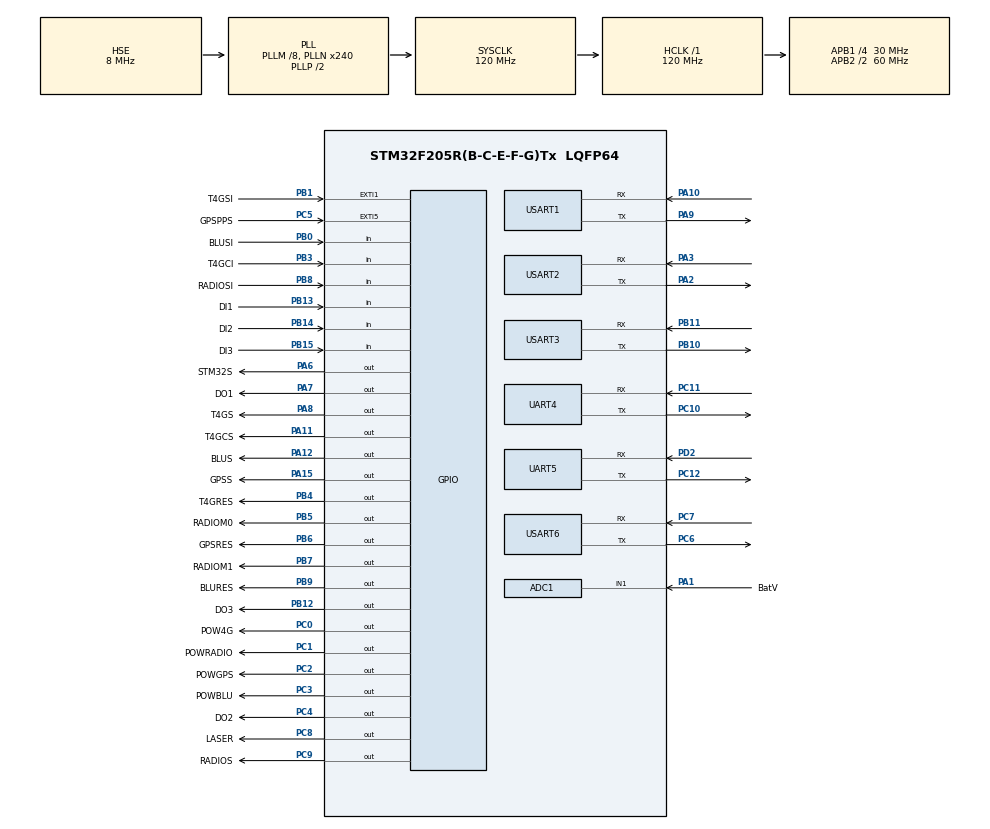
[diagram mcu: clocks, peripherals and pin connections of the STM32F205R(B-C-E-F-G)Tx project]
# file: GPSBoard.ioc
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ADC1.Channel-0\#ChannelRegularConversion=ADC_CHANNEL_1
ADC1.NbrOfConversionFlag=1
ADC1.Rank-0\#ChannelRegularConversion=1
ADC1.SamplingTime-0\#ChannelRegularConversion=ADC_SAMPLETIME_3CYCLES
ADC1.master=1
Dma.Request0=USART1_RX
Dma.Request1=USART1_TX
Dma.Request10=UART4_RX
Dma.Request11=UART4_TX
Dma.Request2=USART2_RX
Dma.Request3=USART2_TX
Dma.Request4=USART3_RX
Dma.Request5=USART3_TX
Dma.Request6=USART6_RX
Dma.Request7=USART6_TX
Dma.Request8=UART5_RX
Dma.Request9=UART5_TX
Dma.UART4_RX.10.Direction=DMA_PERIPH_TO_MEMORY
Dma.UART4_RX.10.FIFOMode=DMA_FIFOMODE_ENABLE
Dma.UART4_RX.10.FIFOThreshold=DMA_FIFO_THRESHOLD_FULL
Dma.UART4_RX.10.Instance=DMA1_Stream2
Dma.UART4_RX.10.MemBurst=DMA_MBURST_SINGLE
Dma.UART4_RX.10.MemDataAlignment=DMA_MDATAALIGN_BYTE
Dma.UART4_RX.10.MemInc=DMA_MINC_ENABLE
Dma.UART4_RX.10.Mode=DMA_NORMAL
Dma.UART4_RX.10.PeriphBurst=DMA_PBURST_SINGLE
Dma.UART4_RX.10.PeriphDataAlignment=DMA_PDATAALIGN_BYTE
Dma.UART4_RX.10.PeriphInc=DMA_PINC_DISABLE
Dma.UART4_RX.10.Priority=DMA_PRIORITY_LOW
Dma.UART4_TX.11.Direction=DMA_MEMORY_TO_PERIPH
Dma.UART4_TX.11.FIFOMode=DMA_FIFOMODE_ENABLE
Dma.UART4_TX.11.FIFOThreshold=DMA_FIFO_THRESHOLD_FULL
Dma.UART4_TX.11.Instance=DMA1_Stream4
Dma.UART4_TX.11.MemBurst=DMA_MBURST_SINGLE
Dma.UART4_TX.11.MemDataAlignment=DMA_MDATAALIGN_BYTE
Dma.UART4_TX.11.MemInc=DMA_MINC_ENABLE
Dma.UART4_TX.11.Mode=DMA_NORMAL
Dma.UART4_TX.11.PeriphBurst=DMA_PBURST_SINGLE
Dma.UART4_TX.11.PeriphDataAlignment=DMA_PDATAALIGN_BYTE
Dma.UART4_TX.11.PeriphInc=DMA_PINC_DISABLE
Dma.UART4_TX.11.Priority=DMA_PRIORITY_LOW
Dma.UART5_RX.8.Direction=DMA_PERIPH_TO_MEMORY
Dma.UART5_RX.8.FIFOMode=DMA_FIFOMODE_ENABLE
Dma.UART5_RX.8.FIFOThreshold=DMA_FIFO_THRESHOLD_FULL
Dma.UART5_RX.8.Instance=DMA1_Stream0
Dma.UART5_RX.8.MemBurst=DMA_MBURST_SINGLE
Dma.UART5_RX.8.MemDataAlignment=DMA_MDATAALIGN_BYTE
Dma.UART5_RX.8.MemInc=DMA_MINC_ENABLE
Dma.UART5_RX.8.Mode=DMA_NORMAL
Dma.UART5_RX.8.PeriphBurst=DMA_PBURST_SINGLE
Dma.UART5_RX.8.PeriphDataAlignment=DMA_PDATAALIGN_BYTE
Dma.UART5_RX.8.PeriphInc=DMA_PINC_DISABLE
Dma.UART5_RX.8.Priority=DMA_PRIORITY_LOW
Dma.UART5_TX.9.Direction=DMA_MEMORY_TO_PERIPH
Dma.UART5_TX.9.FIFOMode=DMA_FIFOMODE_ENABLE
Dma.UART5_TX.9.FIFOThreshold=DMA_FIFO_THRESHOLD_FULL
Dma.UART5_TX.9.Instance=DMA1_Stream7
Dma.UART5_TX.9.MemBurst=DMA_MBURST_SINGLE
Dma.UART5_TX.9.MemDataAlignment=DMA_MDATAALIGN_BYTE
Dma.UART5_TX.9.MemInc=DMA_MINC_ENABLE
Dma.UART5_TX.9.Mode=DMA_NORMAL
Dma.UART5_TX.9.PeriphBurst=DMA_PBURST_SINGLE
Dma.UART5_TX.9.PeriphDataAlignment=DMA_PDATAALIGN_BYTE
Dma.UART5_TX.9.PeriphInc=DMA_PINC_DISABLE
Dma.UART5_TX.9.Priority=DMA_PRIORITY_LOW
Dma.USART1_RX.0.Direction=DMA_PERIPH_TO_MEMORY
Dma.USART1_RX.0.FIFOMode=DMA_FIFOMODE_ENABLE
Dma.USART1_RX.0.FIFOThreshold=DMA_FIFO_THRESHOLD_FULL
Dma.USART1_RX.0.Instance=DMA2_Stream2
Dma.USART1_RX.0.MemBurst=DMA_MBURST_SINGLE
Dma.USART1_RX.0.MemDataAlignment=DMA_MDATAALIGN_BYTE
Dma.USART1_RX.0.MemInc=DMA_MINC_ENABLE
Dma.USART1_RX.0.Mode=DMA_NORMAL
Dma.USART1_RX.0.PeriphBurst=DMA_PBURST_SINGLE
Dma.USART1_RX.0.PeriphDataAlignment=DMA_PDATAALIGN_BYTE
Dma.USART1_RX.0.PeriphInc=DMA_PINC_DISABLE
Dma.USART1_RX.0.Priority=DMA_PRIORITY_LOW
Dma.USART1_TX.1.Direction=DMA_MEMORY_TO_PERIPH
Dma.USART1_TX.1.FIFOMode=DMA_FIFOMODE_ENABLE
Dma.USART1_TX.1.FIFOThreshold=DMA_FIFO_THRESHOLD_FULL
Dma.USART1_TX.1.Instance=DMA2_Stream7
Dma.USART1_TX.1.MemBurst=DMA_MBURST_SINGLE
Dma.USART1_TX.1.MemDataAlignment=DMA_MDATAALIGN_BYTE
Dma.USART1_TX.1.MemInc=DMA_MINC_ENABLE
Dma.USART1_TX.1.Mode=DMA_NORMAL
Dma.USART1_TX.1.PeriphBurst=DMA_PBURST_SINGLE
Dma.USART1_TX.1.PeriphDataAlignment=DMA_PDATAALIGN_BYTE
Dma.USART1_TX.1.PeriphInc=DMA_PINC_DISABLE
Dma.USART1_TX.1.Priority=DMA_PRIORITY_LOW
Dma.USART2_RX.2.Direction=DMA_PERIPH_TO_MEMORY
Dma.USART2_RX.2.FIFOMode=DMA_FIFOMODE_ENABLE
Dma.USART2_RX.2.FIFOThreshold=DMA_FIFO_THRESHOLD_FULL
Dma.USART2_RX.2.Instance=DMA1_Stream5
Dma.USART2_RX.2.MemBurst=DMA_MBURST_SINGLE
Dma.USART2_RX.2.MemDataAlignment=DMA_MDATAALIGN_BYTE
Dma.USART2_RX.2.MemInc=DMA_MINC_ENABLE
Dma.USART2_RX.2.Mode=DMA_NORMAL
Dma.USART2_RX.2.PeriphBurst=DMA_PBURST_SINGLE
Dma.USART2_RX.2.PeriphDataAlignment=DMA_PDATAALIGN_BYTE
Dma.USART2_RX.2.PeriphInc=DMA_PINC_DISABLE
Dma.USART2_RX.2.Priority=DMA_PRIORITY_LOW
Dma.USART2_TX.3.Direction=DMA_MEMORY_TO_PERIPH
Dma.USART2_TX.3.FIFOMode=DMA_FIFOMODE_ENABLE
Dma.USART2_TX.3.FIFOThreshold=DMA_FIFO_THRESHOLD_FULL
Dma.USART2_TX.3.Instance=DMA1_Stream6
Dma.USART2_TX.3.MemBurst=DMA_MBURST_SINGLE
Dma.USART2_TX.3.MemDataAlignment=DMA_MDATAALIGN_BYTE
Dma.USART2_TX.3.MemInc=DMA_MINC_ENABLE
Dma.USART2_TX.3.Mode=DMA_NORMAL
Dma.USART2_TX.3.PeriphBurst=DMA_PBURST_SINGLE
Dma.USART2_TX.3.PeriphDataAlignment=DMA_PDATAALIGN_BYTE
Dma.USART2_TX.3.PeriphInc=DMA_PINC_DISABLE
Dma.USART2_TX.3.Priority=DMA_PRIORITY_LOW
Dma.USART3_RX.4.Direction=DMA_PERIPH_TO_MEMORY
Dma.USART3_RX.4.FIFOMode=DMA_FIFOMODE_ENABLE
Dma.USART3_RX.4.FIFOThreshold=DMA_FIFO_THRESHOLD_FULL
Dma.USART3_RX.4.Instance=DMA1_Stream1
Dma.USART3_RX.4.MemBurst=DMA_MBURST_SINGLE
Dma.USART3_RX.4.MemDataAlignment=DMA_MDATAALIGN_BYTE
Dma.USART3_RX.4.MemInc=DMA_MINC_ENABLE
Dma.USART3_RX.4.Mode=DMA_NORMAL
Dma.USART3_RX.4.PeriphBurst=DMA_PBURST_SINGLE
Dma.USART3_RX.4.PeriphDataAlignment=DMA_PDATAALIGN_BYTE
Dma.USART3_RX.4.PeriphInc=DMA_PINC_DISABLE
Dma.USART3_RX.4.Priority=DMA_PRIORITY_LOW
Dma.USART3_TX.5.Direction=DMA_MEMORY_TO_PERIPH
Dma.USART3_TX.5.FIFOMode=DMA_FIFOMODE_ENABLE
Dma.USART3_TX.5.FIFOThreshold=DMA_FIFO_THRESHOLD_FULL
Dma.USART3_TX.5.Instance=DMA1_Stream3
Dma.USART3_TX.5.MemBurst=DMA_MBURST_SINGLE
Dma.USART3_TX.5.MemDataAlignment=DMA_MDATAALIGN_BYTE
Dma.USART3_TX.5.MemInc=DMA_MINC_ENABLE
Dma.USART3_TX.5.Mode=DMA_NORMAL
Dma.USART3_TX.5.PeriphBurst=DMA_PBURST_SINGLE
Dma.USART3_TX.5.PeriphDataAlignment=DMA_PDATAALIGN_BYTE
Dma.USART3_TX.5.PeriphInc=DMA_PINC_DISABLE
Dma.USART3_TX.5.Priority=DMA_PRIORITY_LOW
Dma.USART6_RX.6.Direction=DMA_PERIPH_TO_MEMORY
Dma.USART6_RX.6.FIFOMode=DMA_FIFOMODE_ENABLE
Dma.USART6_RX.6.FIFOThreshold=DMA_FIFO_THRESHOLD_FULL
Dma.USART6_RX.6.Instance=DMA2_Stream1
Dma.USART6_RX.6.MemBurst=DMA_MBURST_SINGLE
Dma.USART6_RX.6.MemDataAlignment=DMA_MDATAALIGN_BYTE
Dma.USART6_RX.6.MemInc=DMA_MINC_ENABLE
Dma.USART6_RX.6.Mode=DMA_NORMAL
Dma.USART6_RX.6.PeriphBurst=DMA_PBURST_SINGLE
Dma.USART6_RX.6.PeriphDataAlignment=DMA_PDATAALIGN_BYTE
Dma.USART6_RX.6.PeriphInc=DMA_PINC_DISABLE
Dma.USART6_RX.6.Priority=DMA_PRIORITY_LOW
Dma.USART6_TX.7.Direction=DMA_MEMORY_TO_PERIPH
Dma.USART6_TX.7.FIFOMode=DMA_FIFOMODE_ENABLE
Dma.USART6_TX.7.FIFOThreshold=DMA_FIFO_THRESHOLD_FULL
Dma.USART6_TX.7.Instance=DMA2_Stream6
Dma.USART6_TX.7.MemBurst=DMA_MBURST_SINGLE
Dma.USART6_TX.7.MemDataAlignment=DMA_MDATAALIGN_BYTE
Dma.USART6_TX.7.MemInc=DMA_MINC_ENABLE
Dma.USART6_TX.7.Mode=DMA_NORMAL
Dma.USART6_TX.7.PeriphBurst=DMA_PBURST_SINGLE
Dma.USART6_TX.7.PeriphDataAlignment=DMA_PDATAALIGN_BYTE
Dma.USART6_TX.7.PeriphInc=DMA_PINC_DISABLE
Dma.USART6_TX.7.Priority=DMA_PRIORITY_LOW
FREERTOS.HEAP_NUMBER=4
FREERTOS.Tasks01=defaultTask,0,128,StartDefaultTask,Default,NULL
FREERTOS.configTOTAL_HEAP_SIZE=1024*30
IWDG.Prescaler=IWDG_PRESCALER_32
IWDG.Reload=2048
Mcu.Family=STM32F2
Mcu.Name=STM32F205R(B-C-E-F-G)Tx
Mcu.Package=LQFP64
NVIC.DMA1_Stream0_IRQn=true\:5\:0\:false\:false\:true\:true\:false\:true
NVIC.DMA1_Stream1_IRQn=true\:5\:0\:false\:false\:true\:true\:false\:true
NVIC.DMA1_Stream2_IRQn=true\:5\:0\:false\:false\:true\:true\:false\:true
NVIC.DMA1_Stream3_IRQn=true\:5\:0\:false\:false\:true\:true\:false\:true
NVIC.DMA1_Stream4_IRQn=true\:5\:0\:false\:false\:true\:true\:false\:true
NVIC.DMA1_Stream5_IRQn=true\:5\:0\:false\:false\:true\:true\:false\:true
NVIC.DMA1_Stream6_IRQn=true\:5\:0\:false\:false\:true\:true\:false\:true
NVIC.DMA1_Stream7_IRQn=true\:5\:0\:false\:false\:true\:true\:false\:true
NVIC.DMA2_Stream1_IRQn=true\:5\:0\:false\:false\:true\:true\:false\:true
NVIC.DMA2_Stream2_IRQn=true\:5\:0\:false\:false\:true\:true\:false\:true
NVIC.DMA2_Stream6_IRQn=true\:5\:0\:false\:false\:true\:true\:false\:true
NVIC.DMA2_Stream7_IRQn=true\:5\:0\:false\:false\:true\:true\:false\:true
NVIC.EXTI1_IRQn=true\:5\:0\:false\:false\:true\:true\:true\:true
NVIC.EXTI9_5_IRQn=true\:5\:0\:true\:false\:true\:false\:true\:true
NVIC.PriorityGroup=NVIC_PRIORITYGROUP_4
NVIC.UART4_IRQn=true\:5\:0\:false\:false\:true\:true\:true\:true
NVIC.UART5_IRQn=true\:5\:0\:false\:false\:true\:true\:true\:true
NVIC.USART1_IRQn=true\:5\:0\:false\:false\:true\:true\:true\:true
NVIC.USART2_IRQn=true\:5\:0\:false\:false\:true\:true\:true\:true
NVIC.USART3_IRQn=true\:5\:0\:false\:false\:true\:true\:true\:true
NVIC.USART6_IRQn=true\:5\:0\:false\:false\:true\:true\:true\:true
PA1.GPIO_Label=BatV
PA1.Signal=ADCx_IN1
PA10.Mode=Asynchronous
PA10.Signal=USART1_RX
PA11.GPIO_Label=T4GCS
PA11.Signal=GPIO_Output
PA12.GPIO_Label=BLUS
PA12.Signal=GPIO_Output
PA15.GPIO_Label=GPSS
PA15.Signal=GPIO_Output
PA2.Mode=Asynchronous
PA2.Signal=USART2_TX
PA3.Mode=Asynchronous
PA3.Signal=USART2_RX
PA6.GPIO_Label=STM32S
PA6.Signal=GPIO_Output
PA7.GPIO_Label=DO1
PA7.Signal=GPIO_Output
PA8.GPIO_Label=T4GS
PA8.Signal=GPIO_Output
PA9.Mode=Asynchronous
PA9.Signal=USART1_TX
PB0.GPIO_Label=BLUSI
PB0.Signal=GPIO_Input
PB1.GPIO_Label=T4GSI
PB1.Signal=GPXTI1
PB10.Mode=Asynchronous
PB10.Signal=USART3_TX
PB11.Mode=Asynchronous
PB11.Signal=USART3_RX
PB12.GPIO_Label=DO3
PB12.Signal=GPIO_Output
PB13.GPIO_Label=DI1
PB13.Signal=GPIO_Input
PB14.GPIO_Label=DI2
PB14.Signal=GPIO_Input
PB15.GPIO_Label=DI3
PB15.Signal=GPIO_Input
PB3.GPIO_Label=T4GCI
PB3.Signal=GPIO_Input
PB4.GPIO_Label=T4GRES
PB4.PinState=GPIO_PIN_SET
PB4.Signal=GPIO_Output
PB5.GPIO_Label=RADIOM0
PB5.Signal=GPIO_Output
PB6.GPIO_Label=GPSRES
PB6.PinState=GPIO_PIN_SET
PB6.Signal=GPIO_Output
PB7.GPIO_Label=RADIOM1
PB7.Signal=GPIO_Output
PB8.GPIO_Label=RADIOSI
PB8.Signal=GPIO_Input
PB9.GPIO_Label=BLURES
PB9.PinState=GPIO_PIN_SET
PB9.Signal=GPIO_Output
PC0.GPIO_Label=POW4G
PC0.PinState=GPIO_PIN_SET
PC0.Signal=GPIO_Output
PC1.GPIO_Label=POWRADIO
PC1.PinState=GPIO_PIN_SET
PC1.Signal=GPIO_Output
PC10.Mode=Asynchronous
PC10.Signal=UART4_TX
PC11.Mode=Asynchronous
PC11.Signal=UART4_RX
PC12.Mode=Asynchronous
PC12.Signal=UART5_TX
PC2.GPIO_Label=POWGPS
PC2.PinState=GPIO_PIN_SET
PC2.Signal=GPIO_Output
PC3.GPIO_Label=POWBLU
PC3.PinState=GPIO_PIN_SET
PC3.Signal=GPIO_Output
PC4.GPIO_Label=DO2
PC4.Signal=GPIO_Output
PC5.GPIO_Label=GPSPPS
PC5.Signal=GPXTI5
PC6.Mode=Asynchronous
PC6.Signal=USART6_TX
PC7.Mode=Asynchronous
PC7.Signal=USART6_RX
PC8.GPIO_Label=LASER
PC8.GPIO_ModeDefaultOutputPP=GPIO_MODE_OUTPUT_OD
PC8.Signal=GPIO_Output
PC9.GPIO_Label=RADIOS
PC9.Signal=GPIO_Output
PD2.Mode=Asynchronous
PD2.Signal=UART5_RX
PH0-OSC_IN.Mode=HSE-External-Oscillator
PH0-OSC_IN.Signal=RCC_OSC_IN
PH1-OSC_OUT.Mode=HSE-External-Oscillator
PH1-OSC_OUT.Signal=RCC_OSC_OUT
ProjectManager.HeapSize=0x400
ProjectManager.StackSize=0x2000
ProjectManager.TargetToolchain=MDK-ARM V5
RCC.48MHZClocksFreq_Value=60000000
RCC.AHBFreq_Value=120000000
RCC.APB1CLKDivider=RCC_HCLK_DIV4
RCC.APB1Freq_Value=30000000
RCC.APB1TimFreq_Value=60000000
RCC.APB2CLKDivider=RCC_HCLK_DIV2
RCC.APB2Freq_Value=60000000
RCC.APB2TimFreq_Value=120000000
RCC.CortexFreq_Value=120000000
RCC.HCLKFreq_Value=120000000
RCC.HSE_VALUE=8000000
RCC.HSI_VALUE=16000000
RCC.LSE_VALUE=32768
RCC.PLLM=8
RCC.PLLN=240
RCC.PLLSourceVirtual=RCC_PLLSOURCE_HSE
RCC.SYSCLKFreq_VALUE=120000000
RCC.SYSCLKSource=RCC_SYSCLKSOURCE_PLLCLK
RCC.VCOOutputFreq_Value=240000000
SH.ADCx_IN1.0=ADC1_IN1,IN1
UART4.VirtualMode=Asynchronous
UART5.VirtualMode=Asynchronous
USART1.VirtualMode=VM_ASYNC
USART2.VirtualMode=VM_ASYNC
USART3.VirtualMode=VM_ASYNC
USART6.VirtualMode=VM_ASYNC
VP_FREERTOS_VS_CMSIS_V1.Mode=CMSIS_V1
VP_IWDG_VS_IWDG.Mode=IWDG_Activate
board=custom

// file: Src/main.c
/* USER CODE BEGIN Header */
/**
  ******************************************************************************
  * @file           : main.c
  * @brief          : Main program body
  ******************************************************************************
  * @attention
  *
  * <h2><center>&copy; Copyright (c) 2021 STMicroelectronics.
  * All rights reserved.</center></h2>
  *
  * This software component is licensed by ST under Ultimate Liberty license
  * SLA0044, the "License"; You may not use this file except in compliance with
  * the License. You may obtain a copy of the License at:
  *                             www.st.com/SLA0044
  *
  ******************************************************************************
  */
/* USER CODE END Header */
#include "main.h"
#include "cmsis_os.h"

/* USER CODE BEGIN Includes */
#include "OSTask.h"
#include <cm_backtrace.h>
#include "version.h"
/* USER CODE END Includes */

ADC_HandleTypeDef hadc1;

IWDG_HandleTypeDef hiwdg;

UART_HandleTypeDef huart4;
UART_HandleTypeDef huart5;
UART_HandleTypeDef huart1;
UART_HandleTypeDef huart2;
UART_HandleTypeDef huart3;
UART_HandleTypeDef huart6;
DMA_HandleTypeDef hdma_uart4_rx;
DMA_HandleTypeDef hdma_uart4_tx;
DMA_HandleTypeDef hdma_uart5_rx;
DMA_HandleTypeDef hdma_uart5_tx;
DMA_HandleTypeDef hdma_usart1_rx;
DMA_HandleTypeDef hdma_usart1_tx;
DMA_HandleTypeDef hdma_usart2_rx;
DMA_HandleTypeDef hdma_usart2_tx;
DMA_HandleTypeDef hdma_usart3_rx;
DMA_HandleTypeDef hdma_usart3_tx;
DMA_HandleTypeDef hdma_usart6_rx;
DMA_HandleTypeDef hdma_usart6_tx;

osThreadId defaultTaskHandle;

void SystemClock_Config(void);
static void MX_GPIO_Init(void);
static void MX_DMA_Init(void);
static void MX_USART1_UART_Init(void);
static void MX_USART2_UART_Init(void);
static void MX_USART3_UART_Init(void);
static void MX_USART6_UART_Init(void);
static void MX_UART4_Init(void);
static void MX_UART5_Init(void);
static void MX_ADC1_Init(void);
static void MX_IWDG_Init(void);
void StartDefaultTask(void const * argument);

int main(void)
{

  /* MCU Configuration--------------------------------------------------------*/

  /* Reset of all peripherals, Initializes the Flash interface and the Systick. */
  HAL_Init();

  /* Configure the system clock */
  SystemClock_Config();

  /* Initialize all configured peripherals */
  MX_GPIO_Init();
  MX_DMA_Init();
  MX_USART1_UART_Init();
  MX_USART2_UART_Init();
  MX_USART3_UART_Init();
  MX_USART6_UART_Init();
  MX_UART4_Init();
  MX_UART5_Init();
  MX_ADC1_Init();
  /* USER CODE BEGIN 2 */
#ifdef ENABLE_WATCHDOG
  MX_IWDG_Init();
#endif
	genVersion();
	cm_backtrace_init("GPSBoard", Hardware_Version, Software_Version);

  /* USER CODE END 2 */

  /* Create the thread(s) */
  /* definition and creation of defaultTask */
  osThreadDef(defaultTask, StartDefaultTask, osPriorityNormal, 0, 128);
  defaultTaskHandle = osThreadCreate(osThread(defaultTask), NULL);

  /* Start scheduler */
  osKernelStart();

  /* We should never get here as control is now taken by the scheduler */
  /* Infinite loop */
  while (1)
  {

  }
}

void SystemClock_Config(void)
{
  RCC_OscInitTypeDef RCC_OscInitStruct = {0};
  RCC_ClkInitTypeDef RCC_ClkInitStruct = {0};

  /** Initializes the RCC Oscillators according to the specified parameters
  * in the RCC_OscInitTypeDef structure.
  */
  RCC_OscInitStruct.OscillatorType = RCC_OSCILLATORTYPE_LSI|RCC_OSCILLATORTYPE_HSE;
  RCC_OscInitStruct.HSEState = RCC_HSE_ON;
  RCC_OscInitStruct.LSIState = RCC_LSI_ON;
  RCC_OscInitStruct.PLL.PLLState = RCC_PLL_ON;
  RCC_OscInitStruct.PLL.PLLSource = RCC_PLLSOURCE_HSE;
  RCC_OscInitStruct.PLL.PLLM = 8;
  RCC_OscInitStruct.PLL.PLLN = 240;
  RCC_OscInitStruct.PLL.PLLP = RCC_PLLP_DIV2;
  RCC_OscInitStruct.PLL.PLLQ = 4;
  if (HAL_RCC_OscConfig(&RCC_OscInitStruct) != HAL_OK)
  {
    Error_Handler();
  }
  /** Initializes the CPU, AHB and APB buses clocks
  */
  RCC_ClkInitStruct.ClockType = RCC_CLOCKTYPE_HCLK|RCC_CLOCKTYPE_SYSCLK
                              |RCC_CLOCKTYPE_PCLK1|RCC_CLOCKTYPE_PCLK2;
  RCC_ClkInitStruct.SYSCLKSource = RCC_SYSCLKSOURCE_PLLCLK;
  RCC_ClkInitStruct.AHBCLKDivider = RCC_SYSCLK_DIV1;
  RCC_ClkInitStruct.APB1CLKDivider = RCC_HCLK_DIV4;
  RCC_ClkInitStruct.APB2CLKDivider = RCC_HCLK_DIV2;

  if (HAL_RCC_ClockConfig(&RCC_ClkInitStruct, FLASH_LATENCY_3) != HAL_OK)
  {
    Error_Handler();
  }
}

static void MX_ADC1_Init(void)
{

  ADC_ChannelConfTypeDef sConfig = {0};

  /** Configure the global features of the ADC (Clock, Resolution, Data Alignment and number of conversion)
  */
  hadc1.Instance = ADC1;
  hadc1.Init.ClockPrescaler = ADC_CLOCK_SYNC_PCLK_DIV2;
  hadc1.Init.Resolution = ADC_RESOLUTION_12B;
  hadc1.Init.ScanConvMode = DISABLE;
  hadc1.Init.ContinuousConvMode = DISABLE;
  hadc1.Init.DiscontinuousConvMode = DISABLE;
  hadc1.Init.ExternalTrigConvEdge = ADC_EXTERNALTRIGCONVEDGE_NONE;
  hadc1.Init.ExternalTrigConv = ADC_SOFTWARE_START;
  hadc1.Init.DataAlign = ADC_DATAALIGN_RIGHT;
  hadc1.Init.NbrOfConversion = 1;
  hadc1.Init.DMAContinuousRequests = DISABLE;
  hadc1.Init.EOCSelection = ADC_EOC_SINGLE_CONV;
  if (HAL_ADC_Init(&hadc1) != HAL_OK)
  {
    Error_Handler();
  }
  /** Configure for the selected ADC regular channel its corresponding rank in the sequencer and its sample time.
  */
  sConfig.Channel = ADC_CHANNEL_1;
  sConfig.Rank = 1;
  sConfig.SamplingTime = ADC_SAMPLETIME_3CYCLES;
  if (HAL_ADC_ConfigChannel(&hadc1, &sConfig) != HAL_OK)
  {
    Error_Handler();
  }

}

static void MX_IWDG_Init(void)
{

  hiwdg.Instance = IWDG;
  hiwdg.Init.Prescaler = IWDG_PRESCALER_32;
  hiwdg.Init.Reload = 2048;
  if (HAL_IWDG_Init(&hiwdg) != HAL_OK)
  {
    Error_Handler();
  }

}

static void MX_UART4_Init(void)
{

  huart4.Instance = UART4;
  huart4.Init.BaudRate = 115200;
  huart4.Init.WordLength = UART_WORDLENGTH_8B;
  huart4.Init.StopBits = UART_STOPBITS_1;
  huart4.Init.Parity = UART_PARITY_NONE;
  huart4.Init.Mode = UART_MODE_TX_RX;
  huart4.Init.HwFlowCtl = UART_HWCONTROL_NONE;
  huart4.Init.OverSampling = UART_OVERSAMPLING_16;
  if (HAL_UART_Init(&huart4) != HAL_OK)
  {
    Error_Handler();
  }

}

static void MX_UART5_Init(void)
{

  huart5.Instance = UART5;
  huart5.Init.BaudRate = 115200;
  huart5.Init.WordLength = UART_WORDLENGTH_8B;
  huart5.Init.StopBits = UART_STOPBITS_1;
  huart5.Init.Parity = UART_PARITY_NONE;
  huart5.Init.Mode = UART_MODE_TX_RX;
  huart5.Init.HwFlowCtl = UART_HWCONTROL_NONE;
  huart5.Init.OverSampling = UART_OVERSAMPLING_16;
  if (HAL_UART_Init(&huart5) != HAL_OK)
  {
    Error_Handler();
  }

}

static void MX_USART1_UART_Init(void)
{

  huart1.Instance = USART1;
  huart1.Init.BaudRate = 115200;
  huart1.Init.WordLength = UART_WORDLENGTH_8B;
  huart1.Init.StopBits = UART_STOPBITS_1;
  huart1.Init.Parity = UART_PARITY_NONE;
  huart1.Init.Mode = UART_MODE_TX_RX;
  huart1.Init.HwFlowCtl = UART_HWCONTROL_NONE;
  huart1.Init.OverSampling = UART_OVERSAMPLING_16;
  if (HAL_UART_Init(&huart1) != HAL_OK)
  {
    Error_Handler();
  }

}

static void MX_USART2_UART_Init(void)
{

  huart2.Instance = USART2;
  huart2.Init.BaudRate = 115200;
  huart2.Init.WordLength = UART_WORDLENGTH_8B;
  huart2.Init.StopBits = UART_STOPBITS_1;
  huart2.Init.Parity = UART_PARITY_NONE;
  huart2.Init.Mode = UART_MODE_TX_RX;
  huart2.Init.HwFlowCtl = UART_HWCONTROL_NONE;
  huart2.Init.OverSampling = UART_OVERSAMPLING_16;
  if (HAL_UART_Init(&huart2) != HAL_OK)
  {
    Error_Handler();
  }

}

static void MX_USART3_UART_Init(void)
{

  huart3.Instance = USART3;
  huart3.Init.BaudRate = 115200;
  huart3.Init.WordLength = UART_WORDLENGTH_8B;
  huart3.Init.StopBits = UART_STOPBITS_1;
  huart3.Init.Parity = UART_PARITY_NONE;
  huart3.Init.Mode = UART_MODE_TX_RX;
  huart3.Init.HwFlowCtl = UART_HWCONTROL_NONE;
  huart3.Init.OverSampling = UART_OVERSAMPLING_16;
  if (HAL_UART_Init(&huart3) != HAL_OK)
  {
    Error_Handler();
  }

}

static void MX_USART6_UART_Init(void)
{

  huart6.Instance = USART6;
  huart6.Init.BaudRate = 115200;
  huart6.Init.WordLength = UART_WORDLENGTH_8B;
  huart6.Init.StopBits = UART_STOPBITS_1;
  huart6.Init.Parity = UART_PARITY_NONE;
  huart6.Init.Mode = UART_MODE_TX_RX;
  huart6.Init.HwFlowCtl = UART_HWCONTROL_NONE;
  huart6.Init.OverSampling = UART_OVERSAMPLING_16;
  if (HAL_UART_Init(&huart6) != HAL_OK)
  {
    Error_Handler();
  }

}

static void MX_DMA_Init(void)
{

  /* DMA controller clock enable */
  __HAL_RCC_DMA2_CLK_ENABLE();
  __HAL_RCC_DMA1_CLK_ENABLE();

  /* DMA interrupt init */
  /* DMA1_Stream0_IRQn interrupt configuration */
  HAL_NVIC_SetPriority(DMA1_Stream0_IRQn, 5, 0);
  HAL_NVIC_EnableIRQ(DMA1_Stream0_IRQn);
  /* DMA1_Stream1_IRQn interrupt configuration */
  HAL_NVIC_SetPriority(DMA1_Stream1_IRQn, 5, 0);
  HAL_NVIC_EnableIRQ(DMA1_Stream1_IRQn);
  /* DMA1_Stream2_IRQn interrupt configuration */
  HAL_NVIC_SetPriority(DMA1_Stream2_IRQn, 5, 0);
  HAL_NVIC_EnableIRQ(DMA1_Stream2_IRQn);
  /* DMA1_Stream3_IRQn interrupt configuration */
  HAL_NVIC_SetPriority(DMA1_Stream3_IRQn, 5, 0);
  HAL_NVIC_EnableIRQ(DMA1_Stream3_IRQn);
  /* DMA1_Stream4_IRQn interrupt configuration */
  HAL_NVIC_SetPriority(DMA1_Stream4_IRQn, 5, 0);
  HAL_NVIC_EnableIRQ(DMA1_Stream4_IRQn);
  /* DMA1_Stream5_IRQn interrupt configuration */
  HAL_NVIC_SetPriority(DMA1_Stream5_IRQn, 5, 0);
  HAL_NVIC_EnableIRQ(DMA1_Stream5_IRQn);
  /* DMA1_Stream6_IRQn interrupt configuration */
  HAL_NVIC_SetPriority(DMA1_Stream6_IRQn, 5, 0);
  HAL_NVIC_EnableIRQ(DMA1_Stream6_IRQn);
  /* DMA1_Stream7_IRQn interrupt configuration */
  HAL_NVIC_SetPriority(DMA1_Stream7_IRQn, 5, 0);
  HAL_NVIC_EnableIRQ(DMA1_Stream7_IRQn);
  /* DMA2_Stream1_IRQn interrupt configuration */
  HAL_NVIC_SetPriority(DMA2_Stream1_IRQn, 5, 0);
  HAL_NVIC_EnableIRQ(DMA2_Stream1_IRQn);
  /* DMA2_Stream2_IRQn interrupt configuration */
  HAL_NVIC_SetPriority(DMA2_Stream2_IRQn, 5, 0);
  HAL_NVIC_EnableIRQ(DMA2_Stream2_IRQn);
  /* DMA2_Stream6_IRQn interrupt configuration */
  HAL_NVIC_SetPriority(DMA2_Stream6_IRQn, 5, 0);
  HAL_NVIC_EnableIRQ(DMA2_Stream6_IRQn);
  /* DMA2_Stream7_IRQn interrupt configuration */
  HAL_NVIC_SetPriority(DMA2_Stream7_IRQn, 5, 0);
  HAL_NVIC_EnableIRQ(DMA2_Stream7_IRQn);

}

static void MX_GPIO_Init(void)
{
  GPIO_InitTypeDef GPIO_InitStruct = {0};

  /* GPIO Ports Clock Enable */
  __HAL_RCC_GPIOH_CLK_ENABLE();
  __HAL_RCC_GPIOC_CLK_ENABLE();
  __HAL_RCC_GPIOA_CLK_ENABLE();
  __HAL_RCC_GPIOB_CLK_ENABLE();
  __HAL_RCC_GPIOD_CLK_ENABLE();

  /*Configure GPIO pin Output Level */
  HAL_GPIO_WritePin(GPIOC, POW4G_Pin|POWRADIO_Pin|POWGPS_Pin|POWBLU_Pin, GPIO_PIN_SET);

  /*Configure GPIO pin Output Level */
  HAL_GPIO_WritePin(GPIOA, STM32S_Pin|DO1_Pin|T4GS_Pin|T4GCS_Pin
                          |BLUS_Pin|GPSS_Pin, GPIO_PIN_RESET);

  /*Configure GPIO pin Output Level */
  HAL_GPIO_WritePin(GPIOC, DO2_Pin|LASER_Pin|RADIOS_Pin, GPIO_PIN_RESET);

  /*Configure GPIO pin Output Level */
  HAL_GPIO_WritePin(GPIOB, DO3_Pin|RADIOM0_Pin|RADIOM1_Pin, GPIO_PIN_RESET);

  /*Configure GPIO pin Output Level */
  HAL_GPIO_WritePin(GPIOB, T4GRES_Pin|GPSRES_Pin|BLURES_Pin, GPIO_PIN_SET);

  /*Configure GPIO pins : POW4G_Pin POWRADIO_Pin POWGPS_Pin POWBLU_Pin
                           DO2_Pin RADIOS_Pin */
  GPIO_InitStruct.Pin = POW4G_Pin|POWRADIO_Pin|POWGPS_Pin|POWBLU_Pin
                          |DO2_Pin|RADIOS_Pin;
  GPIO_InitStruct.Mode = GPIO_MODE_OUTPUT_PP;
  GPIO_InitStruct.Pull = GPIO_NOPULL;
  GPIO_InitStruct.Speed = GPIO_SPEED_FREQ_LOW;
  HAL_GPIO_Init(GPIOC, &GPIO_InitStruct);

  /*Configure GPIO pins : STM32S_Pin DO1_Pin T4GS_Pin T4GCS_Pin
                           BLUS_Pin GPSS_Pin */
  GPIO_InitStruct.Pin = STM32S_Pin|DO1_Pin|T4GS_Pin|T4GCS_Pin
                          |BLUS_Pin|GPSS_Pin;
  GPIO_InitStruct.Mode = GPIO_MODE_OUTPUT_PP;
  GPIO_InitStruct.Pull = GPIO_NOPULL;
  GPIO_InitStruct.Speed = GPIO_SPEED_FREQ_LOW;
  HAL_GPIO_Init(GPIOA, &GPIO_InitStruct);

  /*Configure GPIO pin : GPSPPS_Pin */
  GPIO_InitStruct.Pin = GPSPPS_Pin;
  GPIO_InitStruct.Mode = GPIO_MODE_IT_RISING;
  GPIO_InitStruct.Pull = GPIO_NOPULL;
  HAL_GPIO_Init(GPSPPS_GPIO_Port, &GPIO_InitStruct);

  /*Configure GPIO pins : BLUSI_Pin DI1_Pin DI2_Pin DI3_Pin
                           T4GCI_Pin RADIOSI_Pin */
  GPIO_InitStruct.Pin = BLUSI_Pin|DI1_Pin|DI2_Pin|DI3_Pin
                          |T4GCI_Pin|RADIOSI_Pin;
  GPIO_InitStruct.Mode = GPIO_MODE_INPUT;
  GPIO_InitStruct.Pull = GPIO_NOPULL;
  HAL_GPIO_Init(GPIOB, &GPIO_InitStruct);

  /*Configure GPIO pin : T4GSI_Pin */
  GPIO_InitStruct.Pin = T4GSI_Pin;
  GPIO_InitStruct.Mode = GPIO_MODE_IT_RISING;
  GPIO_InitStruct.Pull = GPIO_NOPULL;
  HAL_GPIO_Init(T4GSI_GPIO_Port, &GPIO_InitStruct);

  /*Configure GPIO pins : DO3_Pin T4GRES_Pin RADIOM0_Pin GPSRES_Pin
                           RADIOM1_Pin BLURES_Pin */
  GPIO_InitStruct.Pin = DO3_Pin|T4GRES_Pin|RADIOM0_Pin|GPSRES_Pin
                          |RADIOM1_Pin|BLURES_Pin;
  GPIO_InitStruct.Mode = GPIO_MODE_OUTPUT_PP;
  GPIO_InitStruct.Pull = GPIO_NOPULL;
  GPIO_InitStruct.Speed = GPIO_SPEED_FREQ_LOW;
  HAL_GPIO_Init(GPIOB, &GPIO_InitStruct);

  /*Configure GPIO pin : LASER_Pin */
  GPIO_InitStruct.Pin = LASER_Pin;
  GPIO_InitStruct.Mode = GPIO_MODE_OUTPUT_OD;
  GPIO_InitStruct.Pull = GPIO_NOPULL;
  GPIO_InitStruct.Speed = GPIO_SPEED_FREQ_LOW;
  HAL_GPIO_Init(LASER_GPIO_Port, &GPIO_InitStruct);

  /* EXTI interrupt init*/
  HAL_NVIC_SetPriority(EXTI1_IRQn, 5, 0);
  HAL_NVIC_EnableIRQ(EXTI1_IRQn);

  HAL_NVIC_SetPriority(EXTI9_5_IRQn, 5, 0);
  HAL_NVIC_EnableIRQ(EXTI9_5_IRQn);

}

void StartDefaultTask(void const * argument)
{
  /* USER CODE BEGIN 5 */
	User_Init();
  /* Infinite loop */
  for(;;)
  {
    osDelay(1);
  }
  /* USER CODE END 5 */
}

void Error_Handler(void)
{
}

#ifdef  USE_FULL_ASSERT
/**
  * @brief  Reports the name of the source file and the source line number
  *         where the assert_param error has occurred.
  * @param  file: pointer to the source file name
  * @param  line: assert_param error line source number
  * @retval None
  */
void assert_failed(uint8_t *file, uint32_t line)
{
  /* USER CODE BEGIN 6 */
  /* User can add his own implementation to report the file name and line number,
     tex: printf("Wrong parameters value: file %s on line %d\r\n", file, line) */
		char stop =1;
	if(getFlashDump())
		return;
  /* User can add his own implementation to report the file name and line number,
     tex: printf("Wrong parameters value: file %s on line %d\r\n", file, line) */
    cm_backtrace_assert(cmb_get_sp(),file,line);

    while (stop) {
    }
  /* USER CODE END 6 */
}
#endif /* USE_FULL_ASSERT */

/************************ (C) COPYRIGHT STMicroelectronics *****END OF FILE****/
